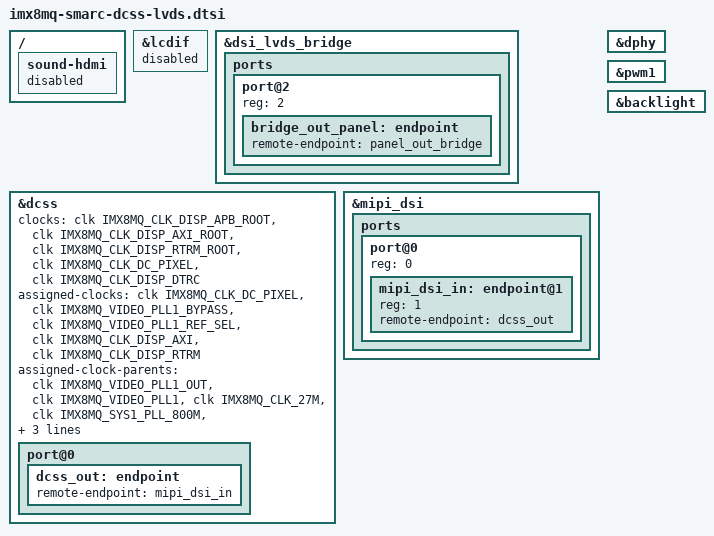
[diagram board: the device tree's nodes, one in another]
// SPDX-License-Identifier: (GPL-2.0 OR MIT)
/*
 * Copyright 2017 NXP
 * Copyright 2024 Embedian, Inc.
 * Copyright (C) 2017-2018 Pengutronix, Lucas Stach <kernel@pengutronix.de>
 */

/ {
	sound-hdmi {
		status = "disabled";
	};
};

#include "imx8mq-smarc-lvds-panel.dtsi"

/delete-node/ &hdmi;

&lcdif {
	status = "disabled";
};

&dsi_lvds_bridge {
	status = "okay";

	ports {
		port@2 {
			reg = <2>;

			bridge_out_panel: endpoint {
				remote-endpoint = <&panel_out_bridge>;
			};
		};
	};
};

&dcss {
	status = "okay";

	clocks = <&clk IMX8MQ_CLK_DISP_APB_ROOT>,
		 <&clk IMX8MQ_CLK_DISP_AXI_ROOT>,
		 <&clk IMX8MQ_CLK_DISP_RTRM_ROOT>,
		 <&clk IMX8MQ_CLK_DC_PIXEL>,
		 <&clk IMX8MQ_CLK_DISP_DTRC>;
	clock-names = "apb", "axi", "rtrm", "pix", "dtrc";
	assigned-clocks = <&clk IMX8MQ_CLK_DC_PIXEL>,
					  <&clk IMX8MQ_VIDEO_PLL1_BYPASS>,
					  <&clk IMX8MQ_VIDEO_PLL1_REF_SEL>,
					  <&clk IMX8MQ_CLK_DISP_AXI>,
					  <&clk IMX8MQ_CLK_DISP_RTRM>;
	assigned-clock-parents = <&clk IMX8MQ_VIDEO_PLL1_OUT>,
							 <&clk IMX8MQ_VIDEO_PLL1>,
							 <&clk IMX8MQ_CLK_27M>,
							 <&clk IMX8MQ_SYS1_PLL_800M>,
							 <&clk IMX8MQ_SYS1_PLL_800M>;
	assigned-clock-rates = <600000000>, <0>, <0>,
						   <800000000>,
						   <400000000>;

	port@0 {
		dcss_out: endpoint {
			remote-endpoint = <&mipi_dsi_in>;
		};
	};
};

&mipi_dsi {
	status = "okay";

	ports {
		#address-cells = <1>;
		#size-cells = <0>;

		port@0 {
			#address-cells = <1>;
			#size-cells = <0>;
			reg = <0>;

			mipi_dsi_in: endpoint@1 {
				reg = <1>;
				remote-endpoint = <&dcss_out>;
			};
		};
	};
};

&dphy {
	status = "okay";
};

&pwm1 {
	status = "okay";
};

&backlight {
	status = "okay";
};
